AUTOSAR XML (schema 4-2-2)
package /Components
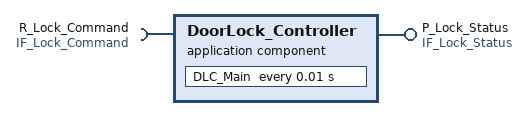
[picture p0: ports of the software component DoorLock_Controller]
  application sw component type DoorLock_Controller
    provide port P_Lock_Status: provided-interface=IF_Lock_Status
    require port R_Lock_Command: required-interface=IF_Lock_Command
    behavior DoorLock_Controller_InternalBehavior
      data received event DLC_LockCmd_Received: start-on-event=DLC_Main
      init event DLC_Init_Event: start-on-event=DLC_Main
      timing event DLC_10ms_Event: start-on-event=DLC_Main, period=0.01
      runnable DLC_Main
        data-receive-point-by-arguments:
          access VA_Read_LockCmd: accessed-variable=R_Lock_Command.lock_cmd
        data-send-points:
          access VA_Write_LockStatus: accessed-variable=P_Lock_Status.lock_status
